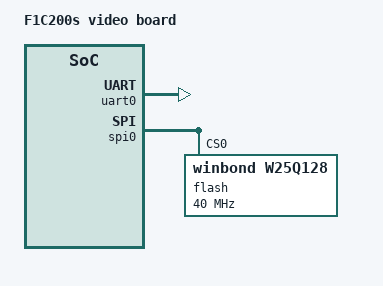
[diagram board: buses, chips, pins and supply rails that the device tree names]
// SPDX-License-Identifier: (GPL-2.0+ OR MIT)
/*
 * Custom F1C200s video board — same as LCTech Pi but debug console
 * on UART0 (PE0 = TX, PE1 = RX), which is where this board's UART
 * header is routed.
 */

#include "suniv-f1c200s-lctech-pi.dts"

/ {
	model = "F1C200s video board";

	aliases {
		serial0 = &uart0;
		spi0 = &spi0;
	};

	chosen {
		stdout-path = "serial0:115200n8";
	};
};

&uart0 {
	pinctrl-names = "default";
	pinctrl-0 = <&uart0_pe_pins>;
	status = "okay";
};

&uart1 {
	status = "disabled";
};

&spi0 {
	pinctrl-names = "default";
	pinctrl-0 = <&spi0_pc_pins>;
	status = "okay";

	flash@0 {
		#address-cells = <1>;
		#size-cells = <1>;
		compatible = "winbond,w25q128", "jedec,spi-nor";
		reg = <0>;
		spi-max-frequency = <40000000>;
	};
};
